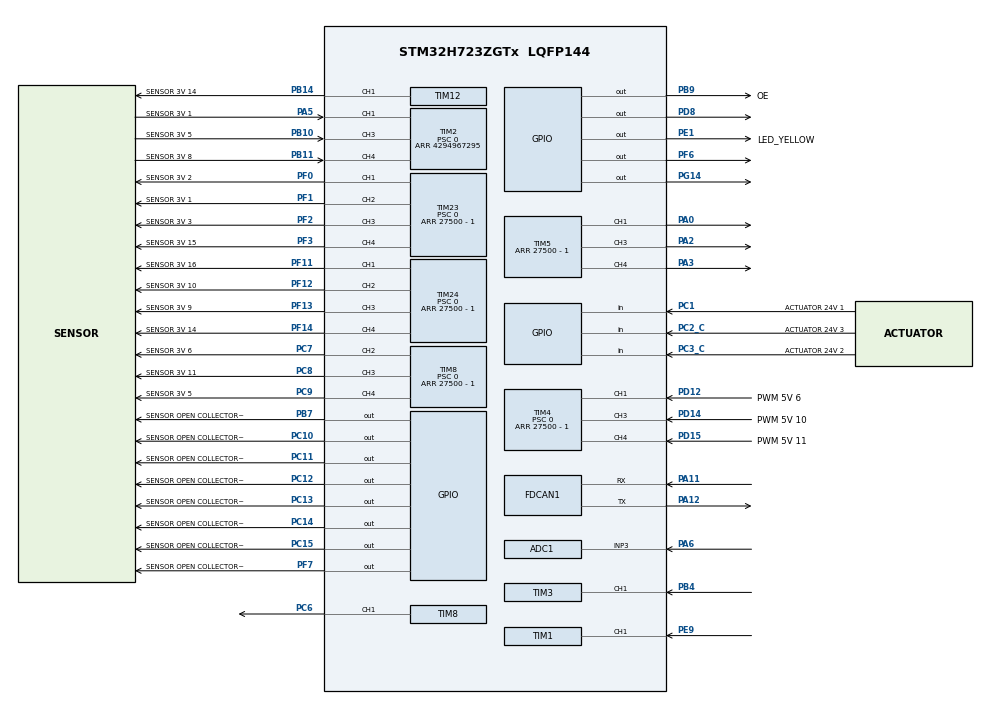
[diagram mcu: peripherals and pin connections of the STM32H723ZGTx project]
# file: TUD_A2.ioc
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ADC1.Channel-1\#ChannelRegularConversion=ADC_CHANNEL_3
ADC1.ContinuousConvMode=DISABLE
ADC1.ConversionDataManagement=ADC_CONVERSIONDATA_DMA_CIRCULAR
ADC1.EOCSelection=ADC_EOC_SEQ_CONV
ADC1.EnableAnalogWatchDog2=false
ADC1.ExternalTrigConv=ADC_EXTERNALTRIG_T6_TRGO
ADC1.ExternalTrigConvEdge=ADC_EXTERNALTRIGCONVEDGE_RISING
ADC1.NbrOfConversion=1
ADC1.NbrOfConversionFlag=1
ADC1.OffsetNumber-1\#ChannelRegularConversion=ADC_OFFSET_NONE
ADC1.OffsetSignedSaturation-1\#ChannelRegularConversion=DISABLE
ADC1.Rank-1\#ChannelRegularConversion=1
ADC1.SamplingTime-1\#ChannelRegularConversion=ADC_SAMPLETIME_1CYCLE_5
ADC1.master=1
Dma.ADC1.0.Direction=DMA_PERIPH_TO_MEMORY
Dma.ADC1.0.EventEnable=DISABLE
Dma.ADC1.0.FIFOMode=DMA_FIFOMODE_DISABLE
Dma.ADC1.0.Instance=DMA1_Stream1
Dma.ADC1.0.MemDataAlignment=DMA_MDATAALIGN_HALFWORD
Dma.ADC1.0.MemInc=DMA_MINC_ENABLE
Dma.ADC1.0.Mode=DMA_CIRCULAR
Dma.ADC1.0.PeriphDataAlignment=DMA_PDATAALIGN_HALFWORD
Dma.ADC1.0.PeriphInc=DMA_PINC_DISABLE
Dma.ADC1.0.Polarity=HAL_DMAMUX_REQ_GEN_RISING
Dma.ADC1.0.Priority=DMA_PRIORITY_LOW
Dma.ADC1.0.RequestNumber=1
Dma.ADC1.0.SignalID=NONE
Dma.ADC1.0.SyncEnable=DISABLE
Dma.ADC1.0.SyncPolarity=HAL_DMAMUX_SYNC_NO_EVENT
Dma.ADC1.0.SyncRequestNumber=1
Dma.ADC1.0.SyncSignalID=NONE
Dma.Request0=ADC1
FDCAN1.CalculateBaudRateNominal=1000000
FDCAN1.CalculateTimeBitNominal=1000
FDCAN1.CalculateTimeQuantumNominal=50.0
FDCAN1.DataPrescaler=3
FDCAN1.DataSyncJumpWidth=1
FDCAN1.DataTimeSeg1=3
FDCAN1.DataTimeSeg2=1
FDCAN1.FrameFormat=FDCAN_FRAME_FD_BRS
FDCAN1.Mode=FDCAN_MODE_NORMAL
FDCAN1.NominalPrescaler=3
FDCAN1.NominalSyncJumpWidth=2
FDCAN1.NominalTimeSeg1=15
FDCAN1.NominalTimeSeg2=4
FDCAN1.RxFifo0ElmtSize=FDCAN_DATA_BYTES_64
FDCAN1.RxFifo0ElmtsNbr=32
FDCAN1.TxElmtSize=FDCAN_DATA_BYTES_64
FDCAN1.TxFifoQueueElmtsNbr=32
Mcu.Family=STM32H7
Mcu.Name=STM32H723ZGTx
Mcu.Package=LQFP144
NVIC.ADC_IRQn=true\:1\:0\:true\:false\:true\:true\:true\:true
NVIC.DMA1_Stream1_IRQn=true\:1\:0\:true\:false\:true\:false\:true\:true
NVIC.FDCAN1_IT0_IRQn=true\:1\:0\:true\:false\:true\:true\:true\:true
NVIC.FDCAN1_IT1_IRQn=true\:1\:0\:true\:false\:true\:true\:true\:true
NVIC.PriorityGroup=NVIC_PRIORITYGROUP_4
NVIC.TIM15_IRQn=true\:1\:0\:true\:false\:true\:true\:true\:true
NVIC.TIM16_IRQn=true\:1\:0\:true\:false\:true\:true\:true\:true
NVIC.TIM17_IRQn=true\:1\:0\:true\:false\:true\:true\:true\:true
NVIC.TIM1_CC_IRQn=true\:1\:0\:true\:false\:true\:true\:true\:true
NVIC.TIM2_IRQn=true\:0\:0\:false\:false\:true\:true\:true\:true
NVIC.TIM3_IRQn=true\:1\:0\:true\:false\:true\:true\:true\:true
NVIC.TIM4_IRQn=true\:1\:0\:true\:false\:true\:true\:true\:true
NVIC.TIM5_IRQn=true\:1\:0\:true\:false\:true\:true\:true\:true
NVIC.TIM6_DAC_IRQn=true\:1\:0\:true\:false\:true\:true\:true\:true
NVIC.TIM7_IRQn=true\:1\:0\:true\:false\:true\:true\:true\:true
NVIC.TIM8_CC_IRQn=true\:1\:0\:true\:false\:true\:true\:true\:true
NVIC.TIM8_TRG_COM_TIM14_IRQn=true\:1\:0\:true\:false\:true\:true\:true\:true
NVIC.TIM8_UP_TIM13_IRQn=true\:1\:0\:true\:false\:true\:true\:true\:true
PA0.Signal=S_TIM5_CH1
PA11.Mode=FDCAN_Activate
PA11.Signal=FDCAN1_RX
PA12.Mode=FDCAN_Activate
PA12.Signal=FDCAN1_TX
PA13(JTMS/SWDIO).GPIO_Label=SWDIO
PA13(JTMS/SWDIO).Signal=DEBUG_JTMS-SWDIO
PA2.Signal=S_TIM5_CH3
PA3.Signal=S_TIM5_CH4
PA5.GPIO_Label=SENSOR 3V 1
PA5.GPIO_PuPd=GPIO_PULLDOWN
PA5.Signal=S_TIM2_CH1_ETR
PA6.Signal=ADCx_INP3
PB10.GPIO_Label=SENSOR 3V 5
PB10.GPIO_PuPd=GPIO_NOPULL
PB10.Signal=S_TIM2_CH3
PB11.GPIO_Label=SENSOR 3V 8
PB11.GPIO_PuPd=GPIO_NOPULL
PB11.Signal=S_TIM2_CH4
PB14.GPIO_Label=SENSOR 3V 14
PB14.Signal=S_TIM12_CH1
PB4(NJTRST).GPIO_PuPd=GPIO_PULLDOWN
PB4(NJTRST).Signal=S_TIM3_CH1
PB7.GPIO_Label=SENSOR OPEN COLLECTOR 6
PB7.GPIO_PuPd=GPIO_PULLDOWN
PB7.Signal=GPIO_Output
PB9.GPIO_Label=OE
PB9.GPIO_PuPd=GPIO_PULLDOWN
PB9.PinState=GPIO_PIN_SET
PB9.Signal=GPIO_Output
PC1.GPIO_Label=ACTUATOR 24V 1
PC1.GPIO_PuPd=GPIO_PULLDOWN
PC1.Signal=GPIO_Input
PC10.GPIO_Label=SENSOR OPEN COLLECTOR 7
PC10.GPIO_PuPd=GPIO_PULLDOWN
PC10.Signal=GPIO_Output
PC11.GPIO_Label=SENSOR OPEN COLLECTOR 8
PC11.GPIO_PuPd=GPIO_PULLDOWN
PC11.Signal=GPIO_Output
PC12.GPIO_Label=SENSOR OPEN COLLECTOR 9
PC12.GPIO_PuPd=GPIO_PULLDOWN
PC12.Signal=GPIO_Output
PC13.GPIO_Label=SENSOR OPEN COLLECTOR  1
PC13.GPIO_PuPd=GPIO_PULLDOWN
PC13.Signal=GPIO_Output
PC14-OSC32_IN.GPIO_Label=SENSOR OPEN COLLECTOR 2
PC14-OSC32_IN.GPIO_PuPd=GPIO_PULLDOWN
PC14-OSC32_IN.Signal=GPIO_Output
PC15-OSC32_OUT.GPIO_Label=SENSOR OPEN COLLECTOR 3
PC15-OSC32_OUT.GPIO_PuPd=GPIO_PULLDOWN
PC15-OSC32_OUT.Signal=GPIO_Output
PC2_C.GPIO_Label=ACTUATOR 24V 3
PC2_C.GPIO_PuPd=GPIO_PULLDOWN
PC2_C.Signal=GPIO_Input
PC3_C.GPIO_Label=ACTUATOR 24V 2
PC3_C.GPIO_PuPd=GPIO_PULLDOWN
PC3_C.Signal=GPIO_Input
PC6.GPIO_PuPd=GPIO_PULLDOWN
PC6.Signal=S_TIM8_CH1
PC7.GPIO_Label=SENSOR 3V 6
PC7.Signal=S_TIM8_CH2
PC8.GPIO_Label=SENSOR 3V 11
PC8.Signal=S_TIM8_CH3
PC9.GPIO_Label=SENSOR 3V 5
PC9.Signal=S_TIM8_CH4
PD12.GPIO_Label=PWM 5V 6
PD12.Signal=S_TIM4_CH1
PD14.GPIO_Label=PWM 5V 10
PD14.Signal=S_TIM4_CH3
PD15.GPIO_Label=PWM 5V 11
PD15.Signal=S_TIM4_CH4
PD8.GPIO_PuPd=GPIO_PULLDOWN
PD8.Signal=GPIO_Output
PE1.GPIO_Label=LED_YELLOW
PE1.Signal=GPIO_Output
PE9.Signal=S_TIM1_CH1
PF0.GPIO_Label=SENSOR 3V 2
PF0.Mode=PWM Generation1 CH1
PF0.Signal=TIM23_CH1
PF1.GPIO_Label=SENSOR 3V 1
PF1.Signal=S_TIM23_CH2
PF11.GPIO_Label=SENSOR 3V 16
PF11.Mode=PWM Generation1 CH1
PF11.Signal=TIM24_CH1
PF12.GPIO_Label=SENSOR 3V 10
PF12.Signal=S_TIM24_CH2
PF13.GPIO_Label=SENSOR 3V 9
PF13.Signal=S_TIM24_CH3
PF14.GPIO_Label=SENSOR 3V 14
PF14.Signal=S_TIM24_CH4
PF2.GPIO_Label=SENSOR 3V 3
PF2.Signal=S_TIM23_CH3
PF3.GPIO_Label=SENSOR 3V 15
PF3.Signal=S_TIM23_CH4
PF6.Signal=GPIO_Output
PF7.GPIO_Label=SENSOR OPEN COLLECTOR 5
PF7.GPIO_PuPd=GPIO_PULLDOWN
PF7.Signal=GPIO_Output
PG14.Signal=GPIO_Output
PH0-OSC_IN.GPIO_Label=MCO
PH0-OSC_IN.Mode=HSE-External-Clock-Source
PH0-OSC_IN.Signal=RCC_OSC_IN
ProjectManager.HeapSize=0x200
ProjectManager.StackSize=0x400
ProjectManager.TargetToolchain=STM32CubeIDE
RCC.ADCFreq_Value=60000000
RCC.APB1Freq_Value=137500000
RCC.APB2Freq_Value=137500000
RCC.APB3Freq_Value=137500000
RCC.APB4Freq_Value=137500000
RCC.CortexFreq_Value=550000000
RCC.D1PPRE=RCC_APB3_DIV2
RCC.D2PPRE1=RCC_APB1_DIV2
RCC.D2PPRE2=RCC_APB2_DIV2
RCC.D3PPRE=RCC_APB4_DIV2
RCC.DIVM1=4
RCC.DIVM2=1
RCC.DIVN1=275
RCC.DIVN2=30
RCC.DIVP1=1
RCC.DIVP2=4
RCC.DIVQ1=4
RCC.DIVQ2=4
RCC.FDCANCLockSelection=RCC_FDCANCLKSOURCE_PLL2
RCC.HCLKFreq_Value=275000000
RCC.HPRE=RCC_HCLK_DIV2
RCC.HSE_VALUE=8000000
RCC.PLL2FRACN=0
RCC.PLLFRACN=0
RCC.PLLSourceVirtual=RCC_PLLSOURCE_HSE
RCC.SYSCLKFreq_VALUE=550000000
RCC.SYSCLKSource=RCC_SYSCLKSOURCE_PLLCLK
RCC.USBCLockSelection=RCC_USBCLKSOURCE_HSI48
RCC.USBFreq_Value=48000000
SH.ADCx_INP3.0=ADC1_INP3,IN3-Single-Ended
SH.ADCx_INP3.1=ADC2_INP3
SH.S_TIM12_CH1.0=TIM12_CH1,PWM Generation1 CH1
SH.S_TIM1_CH1.0=TIM1_CH1,PWM_Input_1
SH.S_TIM23_CH2.0=TIM23_CH2,PWM Generation2 CH2
SH.S_TIM23_CH3.0=TIM23_CH3,PWM Generation3 CH3
SH.S_TIM23_CH4.0=TIM23_CH4,PWM Generation4 CH4
SH.S_TIM24_CH2.0=TIM24_CH2,PWM Generation2 CH2
SH.S_TIM24_CH3.0=TIM24_CH3,PWM Generation3 CH3
SH.S_TIM24_CH4.0=TIM24_CH4,PWM Generation4 CH4
SH.S_TIM2_CH1_ETR.0=TIM2_CH1,PWM_Input_1
SH.S_TIM2_CH3.0=TIM2_CH3,Input_Capture3_from_TI3
SH.S_TIM2_CH4.0=TIM2_CH4,Input_Capture4_from_TI4
SH.S_TIM3_CH1.0=TIM3_CH1,PWM_Input_1
SH.S_TIM4_CH1.0=TIM4_CH1,PWM_Input_1
SH.S_TIM4_CH3.0=TIM4_CH3,Input_Capture3_from_TI3
SH.S_TIM4_CH4.0=TIM4_CH4,Input_Capture4_from_TI4
SH.S_TIM5_CH1.0=TIM5_CH1,PWM Generation1 CH1
SH.S_TIM5_CH3.0=TIM5_CH3,PWM Generation3 CH3
SH.S_TIM5_CH4.0=TIM5_CH4,PWM Generation4 CH4
SH.S_TIM8_CH1.0=TIM8_CH1,PWM Generation1 CH1
SH.S_TIM8_CH2.0=TIM8_CH2,PWM Generation2 CH2
SH.S_TIM8_CH3.0=TIM8_CH3,PWM Generation3 CH3
SH.S_TIM8_CH4.0=TIM8_CH4,PWM Generation4 CH4
TIM1.Period=27500 - 1
TIM1.Prescaler=0
TIM12.Channel-PWM\ Generation1\ CH1=TIM_CHANNEL_1
TIM12.Period=27500 - 1
TIM12.Prescaler=0
TIM16.Period=65535
TIM2.Channel-Input_Capture3_from_TI3=TIM_CHANNEL_3
TIM2.Channel-Input_Capture4_from_TI4=TIM_CHANNEL_4
TIM2.ICPolarity_CH3=TIM_INPUTCHANNELPOLARITY_BOTHEDGE
TIM2.ICPolarity_CH4=TIM_INPUTCHANNELPOLARITY_BOTHEDGE
TIM2.Period=4294967295
TIM2.Prescaler=0
TIM23.Channel-PWM\ Generation1\ CH1=TIM_CHANNEL_1
TIM23.Channel-PWM\ Generation2\ CH2=TIM_CHANNEL_2
TIM23.Channel-PWM\ Generation3\ CH3=TIM_CHANNEL_3
TIM23.Channel-PWM\ Generation4\ CH4=TIM_CHANNEL_4
TIM23.Period=27500 - 1
TIM23.Prescaler=0
TIM24.Channel-PWM\ Generation1\ CH1=TIM_CHANNEL_1
TIM24.Channel-PWM\ Generation2\ CH2=TIM_CHANNEL_2
TIM24.Channel-PWM\ Generation3\ CH3=TIM_CHANNEL_3
TIM24.Channel-PWM\ Generation4\ CH4=TIM_CHANNEL_4
TIM24.Period=27500 - 1
TIM24.Prescaler=0
TIM3.Period=63353
TIM3.Prescaler=0
TIM4.Channel-Input_Capture3_from_TI3=TIM_CHANNEL_3
TIM4.Channel-Input_Capture4_from_TI4=TIM_CHANNEL_4
TIM4.ICPolarity_CH3=TIM_INPUTCHANNELPOLARITY_BOTHEDGE
TIM4.ICPolarity_CH4=TIM_INPUTCHANNELPOLARITY_BOTHEDGE
TIM4.Period=27500 - 1
TIM4.Prescaler=0
TIM5.Channel-PWM\ Generation1\ CH1=TIM_CHANNEL_1
TIM5.Channel-PWM\ Generation3\ CH3=TIM_CHANNEL_3
TIM5.Channel-PWM\ Generation4\ CH4=TIM_CHANNEL_4
TIM5.Period=27500 - 1
TIM6.Period=200 - 1
TIM6.Prescaler=275 -1
TIM6.TIM_MasterOutputTrigger=TIM_TRGO_UPDATE
TIM8.Channel-PWM\ Generation1\ CH1=TIM_CHANNEL_1
TIM8.Channel-PWM\ Generation2\ CH2=TIM_CHANNEL_2
TIM8.Channel-PWM\ Generation3\ CH3=TIM_CHANNEL_3
TIM8.Channel-PWM\ Generation4\ CH4=TIM_CHANNEL_4
TIM8.Period=27500 - 1
TIM8.Prescaler=0
VP_TIM12_VS_ClockSourceINT.Mode=Internal
VP_TIM13_VS_ClockSourceINT.Mode=Enable_Timer
VP_TIM14_VS_ClockSourceINT.Mode=Enable_Timer
VP_TIM15_VS_ClockSourceINT.Mode=Internal
VP_TIM16_VS_ClockSourceINT.Mode=Enable_Timer
VP_TIM17_VS_ClockSourceINT.Mode=Enable_Timer
VP_TIM1_VS_ClockSourceINT.Mode=Internal
VP_TIM23_VS_ClockSourceINT.Mode=Internal
VP_TIM24_VS_ClockSourceINT.Mode=Internal
VP_TIM2_VS_ClockSourceINT.Mode=Internal
VP_TIM3_VS_ClockSourceINT.Mode=Internal
VP_TIM4_VS_ClockSourceINT.Mode=Internal
VP_TIM5_VS_ClockSourceINT.Mode=Internal
VP_TIM6_VS_ClockSourceINT.Mode=Enable_Timer
VP_TIM7_VS_ClockSourceINT.Mode=Enable_Timer
VP_TIM8_VS_ClockSourceINT.Mode=Internal
board=NUCLEO-H723ZG

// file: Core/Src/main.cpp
/* USER CODE BEGIN Header */
/**
  ******************************************************************************
  * @file           : main.c
  * @brief          : Main program body
  ******************************************************************************
  * @attention
  *
  * Copyright (c) 2023 STMicroelectronics.
  * All rights reserved.
  *
  * This software is licensed under terms that can be found in the LICENSE file
  * in the root directory of this software component.
  * If no LICENSE file comes with this software, it is provided AS-IS.
  *
  ******************************************************************************
  */
/* USER CODE END Header */
#include "main.h"

/* USER CODE BEGIN Includes */
#include "TUDTests.hpp"
/* USER CODE END Includes */

ADC_HandleTypeDef hadc1;
DMA_HandleTypeDef hdma_adc1;

FDCAN_HandleTypeDef hfdcan1;

TIM_HandleTypeDef htim1;
TIM_HandleTypeDef htim2;
TIM_HandleTypeDef htim3;
TIM_HandleTypeDef htim4;
TIM_HandleTypeDef htim5;
TIM_HandleTypeDef htim6;
TIM_HandleTypeDef htim7;
TIM_HandleTypeDef htim8;
TIM_HandleTypeDef htim12;
TIM_HandleTypeDef htim13;
TIM_HandleTypeDef htim14;
TIM_HandleTypeDef htim15;
TIM_HandleTypeDef htim16;
TIM_HandleTypeDef htim17;
TIM_HandleTypeDef htim23;
TIM_HandleTypeDef htim24;

void SystemClock_Config(void);
void PeriphCommonClock_Config(void);
static void MX_GPIO_Init(void);
static void MX_DMA_Init(void);
static void MX_TIM12_Init(void);
static void MX_TIM23_Init(void);
static void MX_TIM1_Init(void);
static void MX_TIM2_Init(void);
static void MX_TIM3_Init(void);
static void MX_TIM24_Init(void);
static void MX_FDCAN1_Init(void);
static void MX_TIM4_Init(void);
static void MX_ADC1_Init(void);
static void MX_TIM8_Init(void);
static void MX_TIM6_Init(void);
static void MX_TIM5_Init(void);
static void MX_TIM7_Init(void);
static void MX_TIM13_Init(void);
static void MX_TIM14_Init(void);
static void MX_TIM15_Init(void);
static void MX_TIM16_Init(void);
static void MX_TIM17_Init(void);

int main(void)
{

  /* MCU Configuration--------------------------------------------------------*/

  /* Reset of all peripherals, Initializes the Flash interface and the Systick. */
  HAL_Init();

  /* Configure the system clock */
  SystemClock_Config();

/* Configure the peripherals common clocks */
  PeriphCommonClock_Config();

  /* Initialize all configured peripherals */
  MX_GPIO_Init();
  MX_DMA_Init();
  MX_TIM12_Init();
  MX_TIM23_Init();
  MX_TIM1_Init();
  MX_TIM2_Init();
  MX_TIM3_Init();
  MX_TIM24_Init();
  MX_FDCAN1_Init();
  MX_TIM4_Init();
  MX_ADC1_Init();
  MX_TIM8_Init();
  MX_TIM6_Init();
  MX_TIM5_Init();
  MX_TIM7_Init();
  MX_TIM13_Init();
  MX_TIM14_Init();
  MX_TIM15_Init();
  MX_TIM16_Init();
  MX_TIM17_Init();
  /* USER CODE BEGIN 2 */

  TUDTests::setup();

  HAL_TIM_IC_Start_IT(&htim4, TIM_CHANNEL_1);   // main channel
  HAL_TIM_IC_Start(&htim4, TIM_CHANNEL_2);   // indirect channel

  /* USER CODE END 2 */

  /* Infinite loop */
  /* USER CODE BEGIN WHILE */

  while (1)
  {

		TUDTests::loop();
    /* USER CODE END WHILE */

  }
}

void SystemClock_Config(void)
{
  RCC_OscInitTypeDef RCC_OscInitStruct = {0};
  RCC_ClkInitTypeDef RCC_ClkInitStruct = {0};

  /** Supply configuration update enable
  */
  HAL_PWREx_ConfigSupply(PWR_LDO_SUPPLY);

  /** Configure the main internal regulator output voltage
  */
  __HAL_PWR_VOLTAGESCALING_CONFIG(PWR_REGULATOR_VOLTAGE_SCALE0);

  while(!__HAL_PWR_GET_FLAG(PWR_FLAG_VOSRDY)) {}

  /** Initializes the RCC Oscillators according to the specified parameters
  * in the RCC_OscInitTypeDef structure.
  */
  RCC_OscInitStruct.OscillatorType = RCC_OSCILLATORTYPE_HSE;
  RCC_OscInitStruct.HSEState = RCC_HSE_BYPASS;
  RCC_OscInitStruct.PLL.PLLState = RCC_PLL_ON;
  RCC_OscInitStruct.PLL.PLLSource = RCC_PLLSOURCE_HSE;
  RCC_OscInitStruct.PLL.PLLM = 4;
  RCC_OscInitStruct.PLL.PLLN = 275;
  RCC_OscInitStruct.PLL.PLLP = 1;
  RCC_OscInitStruct.PLL.PLLQ = 4;
  RCC_OscInitStruct.PLL.PLLR = 2;
  RCC_OscInitStruct.PLL.PLLRGE = RCC_PLL1VCIRANGE_1;
  RCC_OscInitStruct.PLL.PLLVCOSEL = RCC_PLL1VCOWIDE;
  RCC_OscInitStruct.PLL.PLLFRACN = 0;
  if (HAL_RCC_OscConfig(&RCC_OscInitStruct) != HAL_OK)
  {
    Error_Handler();
  }

  /** Initializes the CPU, AHB and APB buses clocks
  */
  RCC_ClkInitStruct.ClockType = RCC_CLOCKTYPE_HCLK|RCC_CLOCKTYPE_SYSCLK
                              |RCC_CLOCKTYPE_PCLK1|RCC_CLOCKTYPE_PCLK2
                              |RCC_CLOCKTYPE_D3PCLK1|RCC_CLOCKTYPE_D1PCLK1;
  RCC_ClkInitStruct.SYSCLKSource = RCC_SYSCLKSOURCE_PLLCLK;
  RCC_ClkInitStruct.SYSCLKDivider = RCC_SYSCLK_DIV1;
  RCC_ClkInitStruct.AHBCLKDivider = RCC_HCLK_DIV2;
  RCC_ClkInitStruct.APB3CLKDivider = RCC_APB3_DIV2;
  RCC_ClkInitStruct.APB1CLKDivider = RCC_APB1_DIV2;
  RCC_ClkInitStruct.APB2CLKDivider = RCC_APB2_DIV2;
  RCC_ClkInitStruct.APB4CLKDivider = RCC_APB4_DIV2;

  if (HAL_RCC_ClockConfig(&RCC_ClkInitStruct, FLASH_LATENCY_3) != HAL_OK)
  {
    Error_Handler();
  }
}

void PeriphCommonClock_Config(void)
{
  RCC_PeriphCLKInitTypeDef PeriphClkInitStruct = {0};

  /** Initializes the peripherals clock
  */
  PeriphClkInitStruct.PeriphClockSelection = RCC_PERIPHCLK_ADC|RCC_PERIPHCLK_FDCAN;
  PeriphClkInitStruct.PLL2.PLL2M = 1;
  PeriphClkInitStruct.PLL2.PLL2N = 30;
  PeriphClkInitStruct.PLL2.PLL2P = 4;
  PeriphClkInitStruct.PLL2.PLL2Q = 4;
  PeriphClkInitStruct.PLL2.PLL2R = 2;
  PeriphClkInitStruct.PLL2.PLL2RGE = RCC_PLL2VCIRANGE_3;
  PeriphClkInitStruct.PLL2.PLL2VCOSEL = RCC_PLL2VCOWIDE;
  PeriphClkInitStruct.PLL2.PLL2FRACN = 0;
  PeriphClkInitStruct.FdcanClockSelection = RCC_FDCANCLKSOURCE_PLL2;
  PeriphClkInitStruct.AdcClockSelection = RCC_ADCCLKSOURCE_PLL2;
  if (HAL_RCCEx_PeriphCLKConfig(&PeriphClkInitStruct) != HAL_OK)
  {
    Error_Handler();
  }
}

static void MX_ADC1_Init(void)
{

  ADC_MultiModeTypeDef multimode = {0};
  ADC_ChannelConfTypeDef sConfig = {0};

  /** Common config
  */
  hadc1.Instance = ADC1;
  hadc1.Init.ClockPrescaler = ADC_CLOCK_ASYNC_DIV1;
  hadc1.Init.Resolution = ADC_RESOLUTION_16B;
  hadc1.Init.ScanConvMode = ADC_SCAN_DISABLE;
  hadc1.Init.EOCSelection = ADC_EOC_SEQ_CONV;
  hadc1.Init.LowPowerAutoWait = DISABLE;
  hadc1.Init.ContinuousConvMode = DISABLE;
  hadc1.Init.NbrOfConversion = 1;
  hadc1.Init.DiscontinuousConvMode = DISABLE;
  hadc1.Init.ExternalTrigConv = ADC_EXTERNALTRIG_T6_TRGO;
  hadc1.Init.ExternalTrigConvEdge = ADC_EXTERNALTRIGCONVEDGE_RISING;
  hadc1.Init.ConversionDataManagement = ADC_CONVERSIONDATA_DMA_CIRCULAR;
  hadc1.Init.Overrun = ADC_OVR_DATA_PRESERVED;
  hadc1.Init.LeftBitShift = ADC_LEFTBITSHIFT_NONE;
  hadc1.Init.OversamplingMode = DISABLE;
  if (HAL_ADC_Init(&hadc1) != HAL_OK)
  {
    Error_Handler();
  }

  /** Configure the ADC multi-mode
  */
  multimode.Mode = ADC_MODE_INDEPENDENT;
  if (HAL_ADCEx_MultiModeConfigChannel(&hadc1, &multimode) != HAL_OK)
  {
    Error_Handler();
  }

  /** Configure Regular Channel
  */
  sConfig.Channel = ADC_CHANNEL_3;
  sConfig.Rank = ADC_REGULAR_RANK_1;
  sConfig.SamplingTime = ADC_SAMPLETIME_1CYCLE_5;
  sConfig.SingleDiff = ADC_SINGLE_ENDED;
  sConfig.OffsetNumber = ADC_OFFSET_NONE;
  sConfig.Offset = 0;
  sConfig.OffsetSignedSaturation = DISABLE;
  if (HAL_ADC_ConfigChannel(&hadc1, &sConfig) != HAL_OK)
  {
    Error_Handler();
  }

}

static void MX_FDCAN1_Init(void)
{

  hfdcan1.Instance = FDCAN1;
  hfdcan1.Init.FrameFormat = FDCAN_FRAME_FD_BRS;
  hfdcan1.Init.Mode = FDCAN_MODE_NORMAL;
  hfdcan1.Init.AutoRetransmission = DISABLE;
  hfdcan1.Init.TransmitPause = DISABLE;
  hfdcan1.Init.ProtocolException = DISABLE;
  hfdcan1.Init.NominalPrescaler = 3;
  hfdcan1.Init.NominalSyncJumpWidth = 2;
  hfdcan1.Init.NominalTimeSeg1 = 15;
  hfdcan1.Init.NominalTimeSeg2 = 4;
  hfdcan1.Init.DataPrescaler = 3;
  hfdcan1.Init.DataSyncJumpWidth = 1;
  hfdcan1.Init.DataTimeSeg1 = 3;
  hfdcan1.Init.DataTimeSeg2 = 1;
  hfdcan1.Init.MessageRAMOffset = 0;
  hfdcan1.Init.StdFiltersNbr = 0;
  hfdcan1.Init.ExtFiltersNbr = 0;
  hfdcan1.Init.RxFifo0ElmtsNbr = 32;
  hfdcan1.Init.RxFifo0ElmtSize = FDCAN_DATA_BYTES_64;
  hfdcan1.Init.RxFifo1ElmtsNbr = 0;
  hfdcan1.Init.RxFifo1ElmtSize = FDCAN_DATA_BYTES_8;
  hfdcan1.Init.RxBuffersNbr = 0;
  hfdcan1.Init.RxBufferSize = FDCAN_DATA_BYTES_8;
  hfdcan1.Init.TxEventsNbr = 0;
  hfdcan1.Init.TxBuffersNbr = 0;
  hfdcan1.Init.TxFifoQueueElmtsNbr = 32;
  hfdcan1.Init.TxFifoQueueMode = FDCAN_TX_FIFO_OPERATION;
  hfdcan1.Init.TxElmtSize = FDCAN_DATA_BYTES_64;
  if (HAL_FDCAN_Init(&hfdcan1) != HAL_OK)
  {
    Error_Handler();
  }

}

static void MX_TIM1_Init(void)
{

  TIM_ClockConfigTypeDef sClockSourceConfig = {0};
  TIM_SlaveConfigTypeDef sSlaveConfig = {0};
  TIM_IC_InitTypeDef sConfigIC = {0};
  TIM_MasterConfigTypeDef sMasterConfig = {0};

  htim1.Instance = TIM1;
  htim1.Init.Prescaler = 0;
  htim1.Init.CounterMode = TIM_COUNTERMODE_UP;
  htim1.Init.Period = 27500 - 1;
  htim1.Init.ClockDivision = TIM_CLOCKDIVISION_DIV1;
  htim1.Init.RepetitionCounter = 0;
  htim1.Init.AutoReloadPreload = TIM_AUTORELOAD_PRELOAD_DISABLE;
  if (HAL_TIM_Base_Init(&htim1) != HAL_OK)
  {
    Error_Handler();
  }
  sClockSourceConfig.ClockSource = TIM_CLOCKSOURCE_INTERNAL;
  if (HAL_TIM_ConfigClockSource(&htim1, &sClockSourceConfig) != HAL_OK)
  {
    Error_Handler();
  }
  if (HAL_TIM_IC_Init(&htim1) != HAL_OK)
  {
    Error_Handler();
  }
  sSlaveConfig.SlaveMode = TIM_SLAVEMODE_RESET;
  sSlaveConfig.InputTrigger = TIM_TS_TI1FP1;
  sSlaveConfig.TriggerPolarity = TIM_INPUTCHANNELPOLARITY_RISING;
  sSlaveConfig.TriggerPrescaler = TIM_ICPSC_DIV1;
  sSlaveConfig.TriggerFilter = 0;
  if (HAL_TIM_SlaveConfigSynchro(&htim1, &sSlaveConfig) != HAL_OK)
  {
    Error_Handler();
  }
  sConfigIC.ICPolarity = TIM_INPUTCHANNELPOLARITY_RISING;
  sConfigIC.ICSelection = TIM_ICSELECTION_DIRECTTI;
  sConfigIC.ICPrescaler = TIM_ICPSC_DIV1;
  sConfigIC.ICFilter = 0;
  if (HAL_TIM_IC_ConfigChannel(&htim1, &sConfigIC, TIM_CHANNEL_1) != HAL_OK)
  {
    Error_Handler();
  }
  sConfigIC.ICPolarity = TIM_INPUTCHANNELPOLARITY_FALLING;
  sConfigIC.ICSelection = TIM_ICSELECTION_INDIRECTTI;
  if (HAL_TIM_IC_ConfigChannel(&htim1, &sConfigIC, TIM_CHANNEL_2) != HAL_OK)
  {
    Error_Handler();
  }
  sMasterConfig.MasterOutputTrigger = TIM_TRGO_RESET;
  sMasterConfig.MasterOutputTrigger2 = TIM_TRGO2_RESET;
  sMasterConfig.MasterSlaveMode = TIM_MASTERSLAVEMODE_DISABLE;
  if (HAL_TIMEx_MasterConfigSynchronization(&htim1, &sMasterConfig) != HAL_OK)
  {
    Error_Handler();
  }

}

static void MX_TIM2_Init(void)
{

  TIM_ClockConfigTypeDef sClockSourceConfig = {0};
  TIM_MasterConfigTypeDef sMasterConfig = {0};
  TIM_IC_InitTypeDef sConfigIC = {0};
  TIM_SlaveConfigTypeDef sSlaveConfig = {0};

  htim2.Instance = TIM2;
  htim2.Init.Prescaler = 0;
  htim2.Init.CounterMode = TIM_COUNTERMODE_UP;
  htim2.Init.Period = 4294967295;
  htim2.Init.ClockDivision = TIM_CLOCKDIVISION_DIV1;
  htim2.Init.AutoReloadPreload = TIM_AUTORELOAD_PRELOAD_DISABLE;
  if (HAL_TIM_Base_Init(&htim2) != HAL_OK)
  {
    Error_Handler();
  }
  sClockSourceConfig.ClockSource = TIM_CLOCKSOURCE_INTERNAL;
  if (HAL_TIM_ConfigClockSource(&htim2, &sClockSourceConfig) != HAL_OK)
  {
    Error_Handler();
  }
  if (HAL_TIM_IC_Init(&htim2) != HAL_OK)
  {
    Error_Handler();
  }
  sMasterConfig.MasterOutputTrigger = TIM_TRGO_RESET;
  sMasterConfig.MasterSlaveMode = TIM_MASTERSLAVEMODE_DISABLE;
  if (HAL_TIMEx_MasterConfigSynchronization(&htim2, &sMasterConfig) != HAL_OK)
  {
    Error_Handler();
  }
  sConfigIC.ICPolarity = TIM_INPUTCHANNELPOLARITY_BOTHEDGE;
  sConfigIC.ICSelection = TIM_ICSELECTION_DIRECTTI;
  sConfigIC.ICPrescaler = TIM_ICPSC_DIV1;
  sConfigIC.ICFilter = 0;
  if (HAL_TIM_IC_ConfigChannel(&htim2, &sConfigIC, TIM_CHANNEL_3) != HAL_OK)
  {
    Error_Handler();
  }
  if (HAL_TIM_IC_ConfigChannel(&htim2, &sConfigIC, TIM_CHANNEL_4) != HAL_OK)
  {
    Error_Handler();
  }
  sSlaveConfig.SlaveMode = TIM_SLAVEMODE_RESET;
  sSlaveConfig.InputTrigger = TIM_TS_TI1FP1;
  sSlaveConfig.TriggerPolarity = TIM_INPUTCHANNELPOLARITY_RISING;
  sSlaveConfig.TriggerPrescaler = TIM_ICPSC_DIV1;
  sSlaveConfig.TriggerFilter = 0;
  if (HAL_TIM_SlaveConfigSynchro(&htim2, &sSlaveConfig) != HAL_OK)
  {
    Error_Handler();
  }
  sConfigIC.ICPolarity = TIM_INPUTCHANNELPOLARITY_RISING;
  if (HAL_TIM_IC_ConfigChannel(&htim2, &sConfigIC, TIM_CHANNEL_1) != HAL_OK)
  {
    Error_Handler();
  }
  sConfigIC.ICPolarity = TIM_INPUTCHANNELPOLARITY_FALLING;
  sConfigIC.ICSelection = TIM_ICSELECTION_INDIRECTTI;
  if (HAL_TIM_IC_ConfigChannel(&htim2, &sConfigIC, TIM_CHANNEL_2) != HAL_OK)
  {
    Error_Handler();
  }

}

static void MX_TIM3_Init(void)
{

  TIM_ClockConfigTypeDef sClockSourceConfig = {0};
  TIM_SlaveConfigTypeDef sSlaveConfig = {0};
  TIM_IC_InitTypeDef sConfigIC = {0};
  TIM_MasterConfigTypeDef sMasterConfig = {0};

  htim3.Instance = TIM3;
  htim3.Init.Prescaler = 0;
  htim3.Init.CounterMode = TIM_COUNTERMODE_UP;
  htim3.Init.Period = 63353;
  htim3.Init.ClockDivision = TIM_CLOCKDIVISION_DIV1;
  htim3.Init.AutoReloadPreload = TIM_AUTORELOAD_PRELOAD_DISABLE;
  if (HAL_TIM_Base_Init(&htim3) != HAL_OK)
  {
    Error_Handler();
  }
  sClockSourceConfig.ClockSource = TIM_CLOCKSOURCE_INTERNAL;
  if (HAL_TIM_ConfigClockSource(&htim3, &sClockSourceConfig) != HAL_OK)
  {
    Error_Handler();
  }
  if (HAL_TIM_IC_Init(&htim3) != HAL_OK)
  {
    Error_Handler();
  }
  sSlaveConfig.SlaveMode = TIM_SLAVEMODE_RESET;
  sSlaveConfig.InputTrigger = TIM_TS_TI1FP1;
  sSlaveConfig.TriggerPolarity = TIM_INPUTCHANNELPOLARITY_RISING;
  sSlaveConfig.TriggerPrescaler = TIM_ICPSC_DIV1;
  sSlaveConfig.TriggerFilter = 0;
  if (HAL_TIM_SlaveConfigSynchro(&htim3, &sSlaveConfig) != HAL_OK)
  {
    Error_Handler();
  }
  sConfigIC.ICPolarity = TIM_INPUTCHANNELPOLARITY_RISING;
  sConfigIC.ICSelection = TIM_ICSELECTION_DIRECTTI;
  sConfigIC.ICPrescaler = TIM_ICPSC_DIV1;
  sConfigIC.ICFilter = 0;
  if (HAL_TIM_IC_ConfigChannel(&htim3, &sConfigIC, TIM_CHANNEL_1) != HAL_OK)
  {
    Error_Handler();
  }
  sConfigIC.ICPolarity = TIM_INPUTCHANNELPOLARITY_FALLING;
  sConfigIC.ICSelection = TIM_ICSELECTION_INDIRECTTI;
  if (HAL_TIM_IC_ConfigChannel(&htim3, &sConfigIC, TIM_CHANNEL_2) != HAL_OK)
  {
    Error_Handler();
  }
  sMasterConfig.MasterOutputTrigger = TIM_TRGO_RESET;
  sMasterConfig.MasterSlaveMode = TIM_MASTERSLAVEMODE_DISABLE;
  if (HAL_TIMEx_MasterConfigSynchronization(&htim3, &sMasterConfig) != HAL_OK)
  {
    Error_Handler();
  }

}

static void MX_TIM4_Init(void)
{

  TIM_ClockConfigTypeDef sClockSourceConfig = {0};
  TIM_SlaveConfigTypeDef sSlaveConfig = {0};
  TIM_IC_InitTypeDef sConfigIC = {0};
  TIM_MasterConfigTypeDef sMasterConfig = {0};

  htim4.Instance = TIM4;
  htim4.Init.Prescaler = 0;
  htim4.Init.CounterMode = TIM_COUNTERMODE_UP;
  htim4.Init.Period = 65535;
  htim4.Init.ClockDivision = TIM_CLOCKDIVISION_DIV1;
  htim4.Init.AutoReloadPreload = TIM_AUTORELOAD_PRELOAD_DISABLE;
  if (HAL_TIM_Base_Init(&htim4) != HAL_OK)
  {
    Error_Handler();
  }
  sClockSourceConfig.ClockSource = TIM_CLOCKSOURCE_INTERNAL;
  if (HAL_TIM_ConfigClockSource(&htim4, &sClockSourceConfig) != HAL_OK)
  {
    Error_Handler();
  }
  if (HAL_TIM_IC_Init(&htim4) != HAL_OK)
  {
    Error_Handler();
  }
  sSlaveConfig.SlaveMode = TIM_SLAVEMODE_RESET;
  sSlaveConfig.InputTrigger = TIM_TS_TI1FP1;
  sSlaveConfig.TriggerPolarity = TIM_INPUTCHANNELPOLARITY_RISING;
  sSlaveConfig.TriggerPrescaler = TIM_ICPSC_DIV1;
  sSlaveConfig.TriggerFilter = 0;
  if (HAL_TIM_SlaveConfigSynchro(&htim4, &sSlaveConfig) != HAL_OK)
  {
    Error_Handler();
  }
  sConfigIC.ICPolarity = TIM_INPUTCHANNELPOLARITY_RISING;
  sConfigIC.ICSelection = TIM_ICSELECTION_DIRECTTI;
  sConfigIC.ICPrescaler = TIM_ICPSC_DIV1;
  sConfigIC.ICFilter = 0;
  if (HAL_TIM_IC_ConfigChannel(&htim4, &sConfigIC, TIM_CHANNEL_1) != HAL_OK)
  {
    Error_Handler();
  }
  sConfigIC.ICPolarity = TIM_INPUTCHANNELPOLARITY_FALLING;
  sConfigIC.ICSelection = TIM_ICSELECTION_INDIRECTTI;
  if (HAL_TIM_IC_ConfigChannel(&htim4, &sConfigIC, TIM_CHANNEL_2) != HAL_OK)
  {
    Error_Handler();
  }
  sMasterConfig.MasterOutputTrigger = TIM_TRGO_RESET;
  sMasterConfig.MasterSlaveMode = TIM_MASTERSLAVEMODE_DISABLE;
  if (HAL_TIMEx_MasterConfigSynchronization(&htim4, &sMasterConfig) != HAL_OK)
  {
    Error_Handler();
  }

}

static void MX_TIM5_Init(void)
{

  TIM_ClockConfigTypeDef sClockSourceConfig = {0};
  TIM_MasterConfigTypeDef sMasterConfig = {0};
  TIM_OC_InitTypeDef sConfigOC = {0};

  htim5.Instance = TIM5;
  htim5.Init.Prescaler = 0;
  htim5.Init.CounterMode = TIM_COUNTERMODE_UP;
  htim5.Init.Period = 27500 - 1;
  htim5.Init.ClockDivision = TIM_CLOCKDIVISION_DIV1;
  htim5.Init.AutoReloadPreload = TIM_AUTORELOAD_PRELOAD_DISABLE;
  if (HAL_TIM_Base_Init(&htim5) != HAL_OK)
  {
    Error_Handler();
  }
  sClockSourceConfig.ClockSource = TIM_CLOCKSOURCE_INTERNAL;
  if (HAL_TIM_ConfigClockSource(&htim5, &sClockSourceConfig) != HAL_OK)
  {
    Error_Handler();
  }
  if (HAL_TIM_PWM_Init(&htim5) != HAL_OK)
  {
    Error_Handler();
  }
  sMasterConfig.MasterOutputTrigger = TIM_TRGO_RESET;
  sMasterConfig.MasterSlaveMode = TIM_MASTERSLAVEMODE_DISABLE;
  if (HAL_TIMEx_MasterConfigSynchronization(&htim5, &sMasterConfig) != HAL_OK)
  {
    Error_Handler();
  }
  sConfigOC.OCMode = TIM_OCMODE_PWM1;
  sConfigOC.Pulse = 0;
  sConfigOC.OCPolarity = TIM_OCPOLARITY_HIGH;
  sConfigOC.OCFastMode = TIM_OCFAST_DISABLE;
  if (HAL_TIM_PWM_ConfigChannel(&htim5, &sConfigOC, TIM_CHANNEL_1) != HAL_OK)
  {
    Error_Handler();
  }
  if (HAL_TIM_PWM_ConfigChannel(&htim5, &sConfigOC, TIM_CHANNEL_3) != HAL_OK)
  {
    Error_Handler();
  }
  if (HAL_TIM_PWM_ConfigChannel(&htim5, &sConfigOC, TIM_CHANNEL_4) != HAL_OK)
  {
    Error_Handler();
  }
  HAL_TIM_MspPostInit(&htim5);

}

static void MX_TIM6_Init(void)
{

  TIM_MasterConfigTypeDef sMasterConfig = {0};

  htim6.Instance = TIM6;
  htim6.Init.Prescaler = 275 -1;
  htim6.Init.CounterMode = TIM_COUNTERMODE_UP;
  htim6.Init.Period = 200 - 1;
  htim6.Init.AutoReloadPreload = TIM_AUTORELOAD_PRELOAD_DISABLE;
  if (HAL_TIM_Base_Init(&htim6) != HAL_OK)
  {
    Error_Handler();
  }
  sMasterConfig.MasterOutputTrigger = TIM_TRGO_UPDATE;
  sMasterConfig.MasterSlaveMode = TIM_MASTERSLAVEMODE_DISABLE;
  if (HAL_TIMEx_MasterConfigSynchronization(&htim6, &sMasterConfig) != HAL_OK)
  {
    Error_Handler();
  }

}

static void MX_TIM7_Init(void)
{

  TIM_MasterConfigTypeDef sMasterConfig = {0};

  htim7.Instance = TIM7;
  htim7.Init.Prescaler = 0;
  htim7.Init.CounterMode = TIM_COUNTERMODE_UP;
  htim7.Init.Period = 65535;
  htim7.Init.AutoReloadPreload = TIM_AUTORELOAD_PRELOAD_DISABLE;
  if (HAL_TIM_Base_Init(&htim7) != HAL_OK)
  {
    Error_Handler();
  }
  sMasterConfig.MasterOutputTrigger = TIM_TRGO_RESET;
  sMasterConfig.MasterSlaveMode = TIM_MASTERSLAVEMODE_DISABLE;
  if (HAL_TIMEx_MasterConfigSynchronization(&htim7, &sMasterConfig) != HAL_OK)
  {
    Error_Handler();
  }

}

static void MX_TIM8_Init(void)
{

  TIM_ClockConfigTypeDef sClockSourceConfig = {0};
  TIM_MasterConfigTypeDef sMasterConfig = {0};
  TIM_OC_InitTypeDef sConfigOC = {0};
  TIM_BreakDeadTimeConfigTypeDef sBreakDeadTimeConfig = {0};

  htim8.Instance = TIM8;
  htim8.Init.Prescaler = 0;
  htim8.Init.CounterMode = TIM_COUNTERMODE_UP;
  htim8.Init.Period = 27500 - 1;
  htim8.Init.ClockDivision = TIM_CLOCKDIVISION_DIV1;
  htim8.Init.RepetitionCounter = 0;
  htim8.Init.AutoReloadPreload = TIM_AUTORELOAD_PRELOAD_DISABLE;
  if (HAL_TIM_Base_Init(&htim8) != HAL_OK)
  {
    Error_Handler();
  }
  sClockSourceConfig.ClockSource = TIM_CLOCKSOURCE_INTERNAL;
  if (HAL_TIM_ConfigClockSource(&htim8, &sClockSourceConfig) != HAL_OK)
  {
    Error_Handler();
  }
  if (HAL_TIM_PWM_Init(&htim8) != HAL_OK)
  {
    Error_Handler();
  }
  sMasterConfig.MasterOutputTrigger = TIM_TRGO_RESET;
  sMasterConfig.MasterOutputTrigger2 = TIM_TRGO2_RESET;
  sMasterConfig.MasterSlaveMode = TIM_MASTERSLAVEMODE_DISABLE;
  if (HAL_TIMEx_MasterConfigSynchronization(&htim8, &sMasterConfig) != HAL_OK)
  {
    Error_Handler();
  }
  sConfigOC.OCMode = TIM_OCMODE_PWM1;
  sConfigOC.Pulse = 0;
  sConfigOC.OCPolarity = TIM_OCPOLARITY_HIGH;
  sConfigOC.OCNPolarity = TIM_OCNPOLARITY_HIGH;
  sConfigOC.OCFastMode = TIM_OCFAST_DISABLE;
  sConfigOC.OCIdleState = TIM_OCIDLESTATE_RESET;
  sConfigOC.OCNIdleState = TIM_OCNIDLESTATE_RESET;
  if (HAL_TIM_PWM_ConfigChannel(&htim8, &sConfigOC, TIM_CHANNEL_1) != HAL_OK)
  {
    Error_Handler();
  }
  if (HAL_TIM_PWM_ConfigChannel(&htim8, &sConfigOC, TIM_CHANNEL_2) != HAL_OK)
  {
    Error_Handler();
  }
  if (HAL_TIM_PWM_ConfigChannel(&htim8, &sConfigOC, TIM_CHANNEL_3) != HAL_OK)
  {
    Error_Handler();
  }
  if (HAL_TIM_PWM_ConfigChannel(&htim8, &sConfigOC, TIM_CHANNEL_4) != HAL_OK)
  {
    Error_Handler();
  }
  sBreakDeadTimeConfig.OffStateRunMode = TIM_OSSR_DISABLE;
  sBreakDeadTimeConfig.OffStateIDLEMode = TIM_OSSI_DISABLE;
  sBreakDeadTimeConfig.LockLevel = TIM_LOCKLEVEL_OFF;
  sBreakDeadTimeConfig.DeadTime = 0;
  sBreakDeadTimeConfig.BreakState = TIM_BREAK_DISABLE;
  sBreakDeadTimeConfig.BreakPolarity = TIM_BREAKPOLARITY_HIGH;
  sBreakDeadTimeConfig.BreakFilter = 0;
  sBreakDeadTimeConfig.Break2State = TIM_BREAK2_DISABLE;
  sBreakDeadTimeConfig.Break2Polarity = TIM_BREAK2POLARITY_HIGH;
  sBreakDeadTimeConfig.Break2Filter = 0;
  sBreakDeadTimeConfig.AutomaticOutput = TIM_AUTOMATICOUTPUT_DISABLE;
  if (HAL_TIMEx_ConfigBreakDeadTime(&htim8, &sBreakDeadTimeConfig) != HAL_OK)
  {
    Error_Handler();
  }
  HAL_TIM_MspPostInit(&htim8);

}

static void MX_TIM12_Init(void)
{

  TIM_ClockConfigTypeDef sClockSourceConfig = {0};
  TIM_MasterConfigTypeDef sMasterConfig = {0};
  TIM_OC_InitTypeDef sConfigOC = {0};

  htim12.Instance = TIM12;
  htim12.Init.Prescaler = 0;
  htim12.Init.CounterMode = TIM_COUNTERMODE_UP;
  htim12.Init.Period = 27500 - 1;
  htim12.Init.ClockDivision = TIM_CLOCKDIVISION_DIV1;
  htim12.Init.AutoReloadPreload = TIM_AUTORELOAD_PRELOAD_DISABLE;
  if (HAL_TIM_Base_Init(&htim12) != HAL_OK)
  {
    Error_Handler();
  }
  sClockSourceConfig.ClockSource = TIM_CLOCKSOURCE_INTERNAL;
  if (HAL_TIM_ConfigClockSource(&htim12, &sClockSourceConfig) != HAL_OK)
  {
    Error_Handler();
  }
  if (HAL_TIM_PWM_Init(&htim12) != HAL_OK)
  {
    Error_Handler();
  }
  sMasterConfig.MasterOutputTrigger = TIM_TRGO_RESET;
  sMasterConfig.MasterSlaveMode = TIM_MASTERSLAVEMODE_DISABLE;
  if (HAL_TIMEx_MasterConfigSynchronization(&htim12, &sMasterConfig) != HAL_OK)
  {
    Error_Handler();
  }
  sConfigOC.OCMode = TIM_OCMODE_PWM1;
  sConfigOC.Pulse = 0;
  sConfigOC.OCPolarity = TIM_OCPOLARITY_HIGH;
  sConfigOC.OCFastMode = TIM_OCFAST_DISABLE;
  if (HAL_TIM_PWM_ConfigChannel(&htim12, &sConfigOC, TIM_CHANNEL_1) != HAL_OK)
  {
    Error_Handler();
  }
  HAL_TIM_MspPostInit(&htim12);

}

static void MX_TIM13_Init(void)
{

  htim13.Instance = TIM13;
  htim13.Init.Prescaler = 0;
  htim13.Init.CounterMode = TIM_COUNTERMODE_UP;
  htim13.Init.Period = 65535;
  htim13.Init.ClockDivision = TIM_CLOCKDIVISION_DIV1;
  htim13.Init.AutoReloadPreload = TIM_AUTORELOAD_PRELOAD_DISABLE;
  if (HAL_TIM_Base_Init(&htim13) != HAL_OK)
  {
    Error_Handler();
  }

}

static void MX_TIM14_Init(void)
{

  htim14.Instance = TIM14;
  htim14.Init.Prescaler = 0;
  htim14.Init.CounterMode = TIM_COUNTERMODE_UP;
  htim14.Init.Period = 65535;
  htim14.Init.ClockDivision = TIM_CLOCKDIVISION_DIV1;
  htim14.Init.AutoReloadPreload = TIM_AUTORELOAD_PRELOAD_DISABLE;
  if (HAL_TIM_Base_Init(&htim14) != HAL_OK)
  {
    Error_Handler();
  }

}

static void MX_TIM15_Init(void)
{

  TIM_ClockConfigTypeDef sClockSourceConfig = {0};
  TIM_MasterConfigTypeDef sMasterConfig = {0};

  htim15.Instance = TIM15;
  htim15.Init.Prescaler = 0;
  htim15.Init.CounterMode = TIM_COUNTERMODE_UP;
  htim15.Init.Period = 65535;
  htim15.Init.ClockDivision = TIM_CLOCKDIVISION_DIV1;
  htim15.Init.RepetitionCounter = 0;
  htim15.Init.AutoReloadPreload = TIM_AUTORELOAD_PRELOAD_DISABLE;
  if (HAL_TIM_Base_Init(&htim15) != HAL_OK)
  {
    Error_Handler();
  }
  sClockSourceConfig.ClockSource = TIM_CLOCKSOURCE_INTERNAL;
  if (HAL_TIM_ConfigClockSource(&htim15, &sClockSourceConfig) != HAL_OK)
  {
    Error_Handler();
  }
  sMasterConfig.MasterOutputTrigger = TIM_TRGO_RESET;
  sMasterConfig.MasterSlaveMode = TIM_MASTERSLAVEMODE_DISABLE;
  if (HAL_TIMEx_MasterConfigSynchronization(&htim15, &sMasterConfig) != HAL_OK)
  {
    Error_Handler();
  }

}

static void MX_TIM16_Init(void)
{

  htim16.Instance = TIM16;
  htim16.Init.Prescaler = 0;
  htim16.Init.CounterMode = TIM_COUNTERMODE_UP;
  htim16.Init.Period = 65535;
  htim16.Init.ClockDivision = TIM_CLOCKDIVISION_DIV1;
  htim16.Init.RepetitionCounter = 0;
  htim16.Init.AutoReloadPreload = TIM_AUTORELOAD_PRELOAD_DISABLE;
  if (HAL_TIM_Base_Init(&htim16) != HAL_OK)
  {
    Error_Handler();
  }

}

static void MX_TIM17_Init(void)
{

  htim17.Instance = TIM17;
  htim17.Init.Prescaler = 0;
  htim17.Init.CounterMode = TIM_COUNTERMODE_UP;
  htim17.Init.Period = 65535;
  htim17.Init.ClockDivision = TIM_CLOCKDIVISION_DIV1;
  htim17.Init.RepetitionCounter = 0;
  htim17.Init.AutoReloadPreload = TIM_AUTORELOAD_PRELOAD_DISABLE;
  if (HAL_TIM_Base_Init(&htim17) != HAL_OK)
  {
    Error_Handler();
  }

}

static void MX_TIM23_Init(void)
{

  TIM_ClockConfigTypeDef sClockSourceConfig = {0};
  TIM_MasterConfigTypeDef sMasterConfig = {0};
  TIM_OC_InitTypeDef sConfigOC = {0};

  htim23.Instance = TIM23;
  htim23.Init.Prescaler = 0;
  htim23.Init.CounterMode = TIM_COUNTERMODE_UP;
  htim23.Init.Period = 27500 - 1;
  htim23.Init.ClockDivision = TIM_CLOCKDIVISION_DIV1;
  htim23.Init.AutoReloadPreload = TIM_AUTORELOAD_PRELOAD_DISABLE;
  if (HAL_TIM_Base_Init(&htim23) != HAL_OK)
  {
    Error_Handler();
  }
  sClockSourceConfig.ClockSource = TIM_CLOCKSOURCE_INTERNAL;
  if (HAL_TIM_ConfigClockSource(&htim23, &sClockSourceConfig) != HAL_OK)
  {
    Error_Handler();
  }
  if (HAL_TIM_PWM_Init(&htim23) != HAL_OK)
  {
    Error_Handler();
  }
  sMasterConfig.MasterOutputTrigger = TIM_TRGO_RESET;
  sMasterConfig.MasterSlaveMode = TIM_MASTERSLAVEMODE_DISABLE;
  if (HAL_TIMEx_MasterConfigSynchronization(&htim23, &sMasterConfig) != HAL_OK)
  {
    Error_Handler();
  }
  sConfigOC.OCMode = TIM_OCMODE_PWM1;
  sConfigOC.Pulse = 0;
  sConfigOC.OCPolarity = TIM_OCPOLARITY_HIGH;
  sConfigOC.OCFastMode = TIM_OCFAST_DISABLE;
  if (HAL_TIM_PWM_ConfigChannel(&htim23, &sConfigOC, TIM_CHANNEL_1) != HAL_OK)
  {
    Error_Handler();
  }
  if (HAL_TIM_PWM_ConfigChannel(&htim23, &sConfigOC, TIM_CHANNEL_2) != HAL_OK)
  {
    Error_Handler();
  }
  if (HAL_TIM_PWM_ConfigChannel(&htim23, &sConfigOC, TIM_CHANNEL_3) != HAL_OK)
  {
    Error_Handler();
  }
  if (HAL_TIM_PWM_ConfigChannel(&htim23, &sConfigOC, TIM_CHANNEL_4) != HAL_OK)
  {
    Error_Handler();
  }
  HAL_TIM_MspPostInit(&htim23);

}

static void MX_TIM24_Init(void)
{

  TIM_ClockConfigTypeDef sClockSourceConfig = {0};
  TIM_MasterConfigTypeDef sMasterConfig = {0};
  TIM_OC_InitTypeDef sConfigOC = {0};

  htim24.Instance = TIM24;
  htim24.Init.Prescaler = 0;
  htim24.Init.CounterMode = TIM_COUNTERMODE_UP;
  htim24.Init.Period = 27500 - 1;
  htim24.Init.ClockDivision = TIM_CLOCKDIVISION_DIV1;
  htim24.Init.AutoReloadPreload = TIM_AUTORELOAD_PRELOAD_DISABLE;
  if (HAL_TIM_Base_Init(&htim24) != HAL_OK)
  {
    Error_Handler();
  }
  sClockSourceConfig.ClockSource = TIM_CLOCKSOURCE_INTERNAL;
  if (HAL_TIM_ConfigClockSource(&htim24, &sClockSourceConfig) != HAL_OK)
  {
    Error_Handler();
  }
  if (HAL_TIM_PWM_Init(&htim24) != HAL_OK)
  {
    Error_Handler();
  }
  sMasterConfig.MasterOutputTrigger = TIM_TRGO_RESET;
  sMasterConfig.MasterSlaveMode = TIM_MASTERSLAVEMODE_DISABLE;
  if (HAL_TIMEx_MasterConfigSynchronization(&htim24, &sMasterConfig) != HAL_OK)
  {
    Error_Handler();
  }
  sConfigOC.OCMode = TIM_OCMODE_PWM1;
  sConfigOC.Pulse = 0;
  sConfigOC.OCPolarity = TIM_OCPOLARITY_HIGH;
  sConfigOC.OCFastMode = TIM_OCFAST_DISABLE;
  if (HAL_TIM_PWM_ConfigChannel(&htim24, &sConfigOC, TIM_CHANNEL_1) != HAL_OK)
  {
    Error_Handler();
  }
  if (HAL_TIM_PWM_ConfigChannel(&htim24, &sConfigOC, TIM_CHANNEL_2) != HAL_OK)
  {
    Error_Handler();
  }
  if (HAL_TIM_PWM_ConfigChannel(&htim24, &sConfigOC, TIM_CHANNEL_3) != HAL_OK)
  {
    Error_Handler();
  }
  if (HAL_TIM_PWM_ConfigChannel(&htim24, &sConfigOC, TIM_CHANNEL_4) != HAL_OK)
  {
    Error_Handler();
  }
  HAL_TIM_MspPostInit(&htim24);

}

static void MX_DMA_Init(void)
{

  /* DMA controller clock enable */
  __HAL_RCC_DMA1_CLK_ENABLE();

  /* DMA interrupt init */
  /* DMA1_Stream1_IRQn interrupt configuration */
  HAL_NVIC_SetPriority(DMA1_Stream1_IRQn, 1, 0);
  HAL_NVIC_EnableIRQ(DMA1_Stream1_IRQn);

}

static void MX_GPIO_Init(void)
{
  GPIO_InitTypeDef GPIO_InitStruct = {0};

  /* GPIO Ports Clock Enable */
  __HAL_RCC_GPIOC_CLK_ENABLE();
  __HAL_RCC_GPIOF_CLK_ENABLE();
  __HAL_RCC_GPIOH_CLK_ENABLE();
  __HAL_RCC_GPIOA_CLK_ENABLE();
  __HAL_RCC_GPIOE_CLK_ENABLE();
  __HAL_RCC_GPIOB_CLK_ENABLE();
  __HAL_RCC_GPIOD_CLK_ENABLE();
  __HAL_RCC_GPIOG_CLK_ENABLE();

  /*Configure GPIO pin Output Level */
  HAL_GPIO_WritePin(GPIOC, SENSOR_OPEN_COLLECTOR_1_Pin|SENSOR_OPEN_COLLECTOR_2_Pin|SENSOR_OPEN_COLLECTOR_3_Pin|SENSOR_OPEN_COLLECTOR_7_Pin
                          |SENSOR_OPEN_COLLECTOR_8_Pin|SENSOR_OPEN_COLLECTOR_9_Pin, GPIO_PIN_RESET);

  /*Configure GPIO pin Output Level */
  HAL_GPIO_WritePin(GPIOF, GPIO_PIN_6|SENSOR_OPEN_COLLECTOR_5_Pin, GPIO_PIN_RESET);

  /*Configure GPIO pin Output Level */
  HAL_GPIO_WritePin(GPIOD, GPIO_PIN_8, GPIO_PIN_RESET);

  /*Configure GPIO pin Output Level */
  HAL_GPIO_WritePin(GPIOG, GPIO_PIN_14, GPIO_PIN_RESET);

  /*Configure GPIO pin Output Level */
  HAL_GPIO_WritePin(SENSOR_OPEN_COLLECTOR_6_GPIO_Port, SENSOR_OPEN_COLLECTOR_6_Pin, GPIO_PIN_RESET);

  /*Configure GPIO pin Output Level */
  HAL_GPIO_WritePin(OE_GPIO_Port, OE_Pin, GPIO_PIN_SET);

  /*Configure GPIO pin Output Level */
  HAL_GPIO_WritePin(LED_YELLOW_GPIO_Port, LED_YELLOW_Pin, GPIO_PIN_RESET);

  /*Configure GPIO pins : SENSOR_OPEN_COLLECTOR_1_Pin SENSOR_OPEN_COLLECTOR_2_Pin SENSOR_OPEN_COLLECTOR_3_Pin SENSOR_OPEN_COLLECTOR_7_Pin
                           SENSOR_OPEN_COLLECTOR_8_Pin SENSOR_OPEN_COLLECTOR_9_Pin */
  GPIO_InitStruct.Pin = SENSOR_OPEN_COLLECTOR_1_Pin|SENSOR_OPEN_COLLECTOR_2_Pin|SENSOR_OPEN_COLLECTOR_3_Pin|SENSOR_OPEN_COLLECTOR_7_Pin
                          |SENSOR_OPEN_COLLECTOR_8_Pin|SENSOR_OPEN_COLLECTOR_9_Pin;
  GPIO_InitStruct.Mode = GPIO_MODE_OUTPUT_PP;
  GPIO_InitStruct.Pull = GPIO_PULLDOWN;
  GPIO_InitStruct.Speed = GPIO_SPEED_FREQ_LOW;
  HAL_GPIO_Init(GPIOC, &GPIO_InitStruct);

  /*Configure GPIO pin : PF6 */
  GPIO_InitStruct.Pin = GPIO_PIN_6;
  GPIO_InitStruct.Mode = GPIO_MODE_OUTPUT_PP;
  GPIO_InitStruct.Pull = GPIO_NOPULL;
  GPIO_InitStruct.Speed = GPIO_SPEED_FREQ_LOW;
  HAL_GPIO_Init(GPIOF, &GPIO_InitStruct);

  /*Configure GPIO pin : SENSOR_OPEN_COLLECTOR_5_Pin */
  GPIO_InitStruct.Pin = SENSOR_OPEN_COLLECTOR_5_Pin;
  GPIO_InitStruct.Mode = GPIO_MODE_OUTPUT_PP;
  GPIO_InitStruct.Pull = GPIO_PULLDOWN;
  GPIO_InitStruct.Speed = GPIO_SPEED_FREQ_LOW;
  HAL_GPIO_Init(SENSOR_OPEN_COLLECTOR_5_GPIO_Port, &GPIO_InitStruct);

  /*Configure GPIO pins : ACTUATOR_24V_1_Pin ACTUATOR_24V_3_Pin ACTUATOR_24V_2_Pin */
  GPIO_InitStruct.Pin = ACTUATOR_24V_1_Pin|ACTUATOR_24V_3_Pin|ACTUATOR_24V_2_Pin;
  GPIO_InitStruct.Mode = GPIO_MODE_INPUT;
  GPIO_InitStruct.Pull = GPIO_PULLDOWN;
  HAL_GPIO_Init(GPIOC, &GPIO_InitStruct);

  /*Configure GPIO pin : PA6 */
  GPIO_InitStruct.Pin = GPIO_PIN_6;
  GPIO_InitStruct.Mode = GPIO_MODE_ANALOG;
  GPIO_InitStruct.Pull = GPIO_NOPULL;
  HAL_GPIO_Init(GPIOA, &GPIO_InitStruct);

  /*Configure GPIO pin : PD8 */
  GPIO_InitStruct.Pin = GPIO_PIN_8;
  GPIO_InitStruct.Mode = GPIO_MODE_OUTPUT_PP;
  GPIO_InitStruct.Pull = GPIO_PULLDOWN;
  GPIO_InitStruct.Speed = GPIO_SPEED_FREQ_LOW;
  HAL_GPIO_Init(GPIOD, &GPIO_InitStruct);

  /*Configure GPIO pin : PG14 */
  GPIO_InitStruct.Pin = GPIO_PIN_14;
  GPIO_InitStruct.Mode = GPIO_MODE_OUTPUT_PP;
  GPIO_InitStruct.Pull = GPIO_NOPULL;
  GPIO_InitStruct.Speed = GPIO_SPEED_FREQ_LOW;
  HAL_GPIO_Init(GPIOG, &GPIO_InitStruct);

  /*Configure GPIO pins : SENSOR_OPEN_COLLECTOR_6_Pin OE_Pin */
  GPIO_InitStruct.Pin = SENSOR_OPEN_COLLECTOR_6_Pin|OE_Pin;
  GPIO_InitStruct.Mode = GPIO_MODE_OUTPUT_PP;
  GPIO_InitStruct.Pull = GPIO_PULLDOWN;
  GPIO_InitStruct.Speed = GPIO_SPEED_FREQ_LOW;
  HAL_GPIO_Init(GPIOB, &GPIO_InitStruct);

  /*Configure GPIO pin : LED_YELLOW_Pin */
  GPIO_InitStruct.Pin = LED_YELLOW_Pin;
  GPIO_InitStruct.Mode = GPIO_MODE_OUTPUT_PP;
  GPIO_InitStruct.Pull = GPIO_NOPULL;
  GPIO_InitStruct.Speed = GPIO_SPEED_FREQ_LOW;
  HAL_GPIO_Init(LED_YELLOW_GPIO_Port, &GPIO_InitStruct);

}

void Error_Handler(void)
{
  __disable_irq();
  while (1)
  {
  }
}
